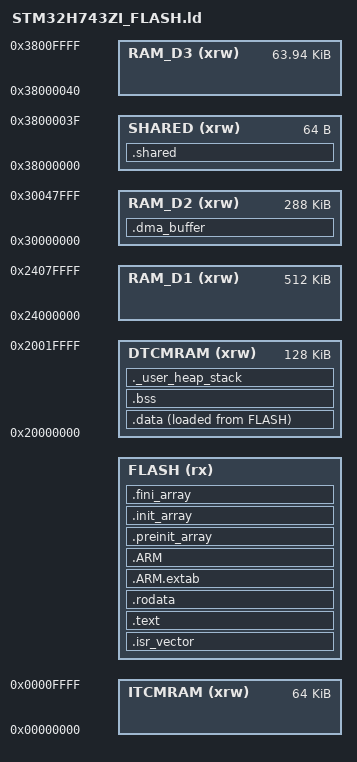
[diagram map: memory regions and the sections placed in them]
/*
*****************************************************************************
**

**  File        : stm32_flash.ld
**
**  Abstract    : Linker script for STM32H743ZI Device with
**                2048KByte FLASH, 1056KByte RAM
**
**                Set heap size, stack size and stack location according
**                to application requirements.
**
**                Set memory bank area and size if external memory is used.
**
**  Target      : STMicroelectronics STM32
**
**  Environment : Atollic TrueSTUDIO(R)
**
**  Distribution: The file is distributed as is, without any warranty
**                of any kind.
**
**  (c)Copyright Atollic AB.
**  You may use this file as-is or modify it according to the needs of your
**  project. This file may only be built (assembled or compiled and linked)
**  using the Atollic TrueSTUDIO(R) product. The use of this file together
**  with other tools than Atollic TrueSTUDIO(R) is not permitted.
**
*****************************************************************************
*/

/*
 * NOTE: IT IS VERY IMPORTANT TO KEEP THIS FILE CONSISTENT WITH ITS
 * BOOTLOADER COUNTERPART.  OTHERWISE UNEXPECTED BEHAVIOUR MAY RESULT!
 */

/* Entry Point */
ENTRY(Reset_Handler)

/* Highest address of the user mode stack */
_estack = ORIGIN(DTCMRAM) + LENGTH(DTCMRAM);    /* end of RAM */

/* Generate a link error if heap and stack don't fit into RAM */
_Min_Heap_Size  = 0x200;        /* required amount of heap  */
_Min_Stack_Size = 0x400;        /* required amount of stack */

FLASH_OFFSET  = DEFINED(USE_BOOTLOADER) ? 128K : 0;
CHECKSUM_SIZE = DEFINED(USE_BOOTLOADER) ? 128 : 0;

/* Specify the memory areas */
MEMORY
{
DTCMRAM (xrw)     : ORIGIN = 0x20000000, LENGTH = 128K
RAM_D1  (xrw)     : ORIGIN = 0x24000000, LENGTH = 512K
RAM_D2  (xrw)     : ORIGIN = 0x30000000, LENGTH = 288K
/*
 * The "SHARED" memory area is used for communication between the
 * application and the bootloader and should not be initialised.
 */
SHARED  (xrw)     : ORIGIN = 0x38000000, LENGTH = 64
RAM_D3  (xrw)     : ORIGIN = 0x38000000 + 64, LENGTH = 64K - 64
ITCMRAM (xrw)     : ORIGIN = 0x00000000, LENGTH = 64K
/*
 * The device has 2048K flash memory consisting of 16 sectors of 128K
 * each, beginning at 0x08000000.  The first sector is used for the
 * bootloader.  The last 128 bytes are reserved for the checksum used
 * by the bootloader to verify the application.
 */
FLASH   (rx)    : ORIGIN = 0x08000000 + FLASH_OFFSET, LENGTH = 2048K - FLASH_OFFSET - CHECKSUM_SIZE
}

/* Define output sections */
SECTIONS
{
/*
 * The "NOLOAD" directive keeps this memory area from being initialised.
 */
   .shared (NOLOAD) :
  {
    . = ALIGN(4);
    _sshared = .;
    __shared_start__ = _sshared;
    *(.shared)
    *(.shared.*)
    KEEP(*(.shared))
    . = ALIGN(4);
    _eshared = .;
    __shared_end__ = _eshared;
  } >SHARED

  /* The startup code goes first into FLASH */
  .isr_vector :
  {
    . = ALIGN(4);
    KEEP(*(.isr_vector)) /* Startup code */
    . = ALIGN(4);
  } >FLASH

  /* The program code and other data goes into FLASH */
  .text :
  {
    . = ALIGN(4);
    *(.text)           /* .text sections (code) */
    *(.text*)          /* .text* sections (code) */
    *(.glue_7)         /* glue arm to thumb code */
    *(.glue_7t)        /* glue thumb to arm code */
    *(.eh_frame)

    KEEP (*(.init))
    KEEP (*(.fini))

    . = ALIGN(4);
    _etext = .;        /* define a global symbols at end of code */
  } >FLASH

  /* Constant data goes into FLASH */
  .rodata :
  {
    . = ALIGN(4);
    *(.rodata)         /* .rodata sections (constants, strings, etc.) */
    *(.rodata*)        /* .rodata* sections (constants, strings, etc.) */
    . = ALIGN(4);
  } >FLASH

  .ARM.extab :
  {
    . = ALIGN(4);
    *(.ARM.extab* .gnu.linkonce.armextab.*)
    . = ALIGN(4);
  } >FLASH

  .ARM :
  {
    . = ALIGN(4);
    __exidx_start = .;
    *(.ARM.exidx*)
    __exidx_end = .;
    . = ALIGN(4);
  } >FLASH

  .preinit_array     :
  {
    . = ALIGN(4);
    PROVIDE_HIDDEN (__preinit_array_start = .);
    KEEP (*(.preinit_array*))
    PROVIDE_HIDDEN (__preinit_array_end = .);
    . = ALIGN(4);
  } >FLASH

  .init_array :
  {
    . = ALIGN(4);
    PROVIDE_HIDDEN (__init_array_start = .);
    KEEP (*(SORT(.init_array.*)))
    KEEP (*(.init_array*))
    PROVIDE_HIDDEN (__init_array_end = .);
    . = ALIGN(4);
  } >FLASH

  .fini_array :
  {
    . = ALIGN(4);
    PROVIDE_HIDDEN (__fini_array_start = .);
    KEEP (*(SORT(.fini_array.*)))
    KEEP (*(.fini_array*))
    PROVIDE_HIDDEN (__fini_array_end = .);
    . = ALIGN(4);
  } >FLASH

  /* used by the startup to initialize data */
  _sidata = LOADADDR(.data);

  /* Initialized data sections goes into RAM, load LMA copy after code */
  .data :
  {
    . = ALIGN(4);
    _sdata = .;        /* create a global symbol at data start */
    *(.data)           /* .data sections */
    *(.data*)          /* .data* sections */

    . = ALIGN(4);
    _edata = .;        /* define a global symbol at data end */
  } >DTCMRAM AT> FLASH

  /* Uninitialized data section */
  . = ALIGN(4);
  .bss :
  {
    /* This is used by the startup in order to initialize the .bss secion */
    _sbss = .;         /* define a global symbol at bss start */
    __bss_start__ = _sbss;
    *(.bss)
    *(.bss*)
    *(COMMON)

    . = ALIGN(4);
    _ebss = .;         /* define a global symbol at bss end */
    __bss_end__ = _ebss;
  } >DTCMRAM

  /* User_heap_stack section, used to check that there is enough RAM left */
  ._user_heap_stack :
  {
    . = ALIGN(8);
    PROVIDE ( end = . );
    PROVIDE ( _end = . );
    . = . + _Min_Heap_Size;
    . = . + _Min_Stack_Size;
    . = ALIGN(8);
  } >DTCMRAM

  .dma_buffer (NOLOAD) :
  {
    *(.dma_buffer)
  } >RAM_D2

  /* Remove information from the standard libraries */
  /DISCARD/ :
  {
    libc.a ( * )
    libm.a ( * )
    libgcc.a ( * )
  }

  .ARM.attributes 0 : { *(.ARM.attributes) }
}
